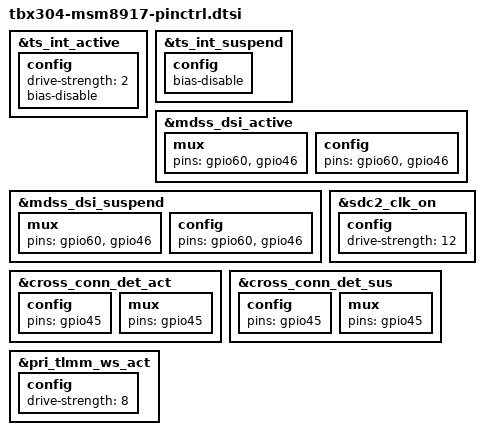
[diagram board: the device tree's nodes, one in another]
&ts_int_active {
    config {
	drive-strength = <2>;
	bias-disable;
	/delete-property/ bias-pull-up;
    };
};

&ts_int_suspend {
    config {
	bias-disable;
	/delete-property/ bias-pull-down;
    };
};

&mdss_dsi_active {
    mux {
	pins = "gpio60", "gpio46";
    };
    config {
	pins = "gpio60", "gpio46";
	/delete-property/ output-high;
    };
};

&mdss_dsi_suspend {
    mux {
	pins = "gpio60", "gpio46";
    };
    config {
	pins = "gpio60", "gpio46";
    };
};

&sdc2_clk_on {
    config {
	drive-strength = <12>;
    };
};

&cross_conn_det_act {
    config {
	pins = "gpio45";
    };
    mux {
	pins = "gpio45";
    };
};

&cross_conn_det_sus {
    config {
	pins = "gpio45";
    };
    mux {
	pins = "gpio45";
    };
};

&pri_tlmm_ws_act {
    config {
	drive-strength = <8>;
	/delete-property/ bias-disable;
	/delete-property/ output-high;
    };
};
